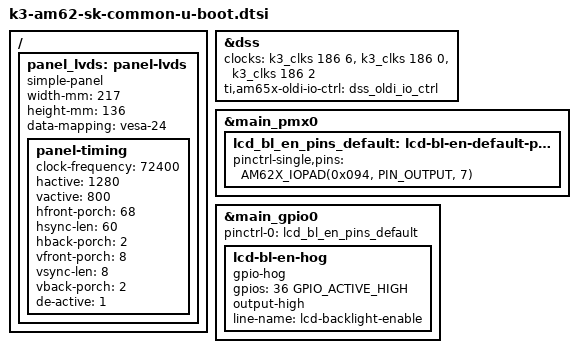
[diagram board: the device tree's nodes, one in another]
// SPDX-License-Identifier: GPL-2.0
/*
 * Common U-Boot dtsi for AM62x SK and derivatives
 * Copyright (C) 2025 Texas Instruments Incorporated - https://www.ti.com/
 */

#include "k3-am625-sk-binman.dtsi"

/ {
	/* ===== CRZ CHANGED START: U-Boot splash panel = Bestar BSD101WX1-300
	 * (10.1" 1280x800 LVDS on OLDI, single link - see tidss_drv.c).
	 * Notes:
	 *  - U-Boot's tidss only reads compatible/panel-timing/data-mapping
	 *    from this node; OLDI ports/companion properties are kernel
	 *    binding material and are intentionally NOT present here.
	 *  - NO backlight phandle: simple-panel probe fails if the phandle
	 *    cannot bind a backlight driver, killing video entirely. The
	 *    backlight enable line is driven by the gpio hog below instead.
	 *  - vanilla TI timings were 1920x1200 (SK LCD1 kit panel). ===== */
	panel_lvds: panel-lvds {
		bootph-pre-ram;
		compatible = "simple-panel";
		status = "okay";
		width-mm = <217>;
		height-mm = <136>;
		data-mapping = "vesa-24";
		panel-timing {
			bootph-pre-ram;
			clock-frequency = <72400>;
			hactive = <1280>;
			vactive = <800>;
			hfront-porch = <68>;
			hsync-len = <60>;
			hback-porch = <2>;
			vfront-porch = <8>;
			vsync-len = <8>;
			vback-porch = <2>;
			de-active = <1>;
		};
	};
	/* ===== CRZ CHANGED END ===== */
};

/* vanilla TI override: U-Boot-resolvable DSS clocks + OLDI io-ctrl syscon */
&dss {
	clocks = <&k3_clks 186 6>,
		<&k3_clks 186 0>,
		<&k3_clks 186 2>;
	ti,am65x-oldi-io-ctrl = <&dss_oldi_io_ctrl>;
};

/* ===== CRZ ADDED START: LCD backlight enable for U-Boot splash =====
 * GPMC0_BE1n.GPIO0_36 gates the backlight supply; drive it high as soon
 * as main_gpio0 probes so the splash is visible (U-Boot's tidss never
 * calls panel_enable_backlight()). Requires CONFIG_GPIO_HOG=y. */
&main_pmx0 {
	lcd_bl_en_pins_default: lcd-bl-en-default-pins {
		pinctrl-single,pins = <
			AM62X_IOPAD(0x094, PIN_OUTPUT, 7) /* (N20) GPMC0_BE1n.GPIO0_36 */
		>;
	};
};

&main_gpio0 {
	pinctrl-names = "default";
	pinctrl-0 = <&lcd_bl_en_pins_default>;

	lcd-bl-en-hog {
		gpio-hog;
		gpios = <36 GPIO_ACTIVE_HIGH>;
		output-high;
		line-name = "lcd-backlight-enable";
	};
};
/* ===== CRZ ADDED END ===== */
